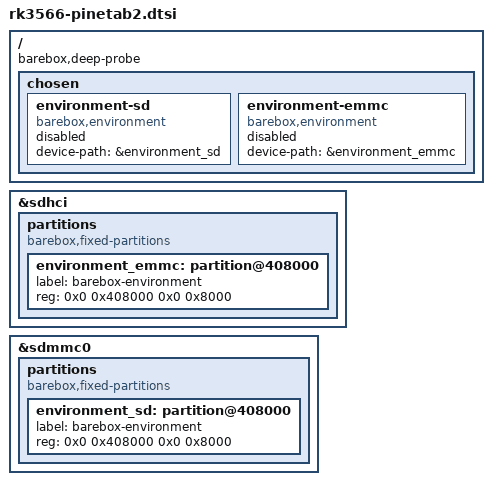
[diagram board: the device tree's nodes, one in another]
// SPDX-License-Identifier: (GPL-2.0+ OR MIT)

#include <arm64/rockchip/rk3566-pinetab2.dtsi>
#include "rk356x.dtsi"

/ {
	barebox,deep-probe;

	chosen: chosen {
		environment-sd {
			compatible = "barebox,environment";
			device-path = &environment_sd;
			status = "disabled";
		};

		environment-emmc {
			compatible = "barebox,environment";
			device-path = &environment_emmc;
			status = "disabled";
		};
	};
};

&sdhci {
	partitions {
		compatible = "barebox,fixed-partitions";
		#address-cells = <2>;
		#size-cells = <2>;

		environment_emmc: partition@408000 {
			label = "barebox-environment";
			reg = <0x0 0x408000 0x0 0x8000>;
		};
	};
};

&sdmmc0 {
	partitions {
		compatible = "barebox,fixed-partitions";
		#address-cells = <2>;
		#size-cells = <2>;

		environment_sd: partition@408000 {
			label = "barebox-environment";
			reg = <0x0 0x408000 0x0 0x8000>;
		};
	};
};
